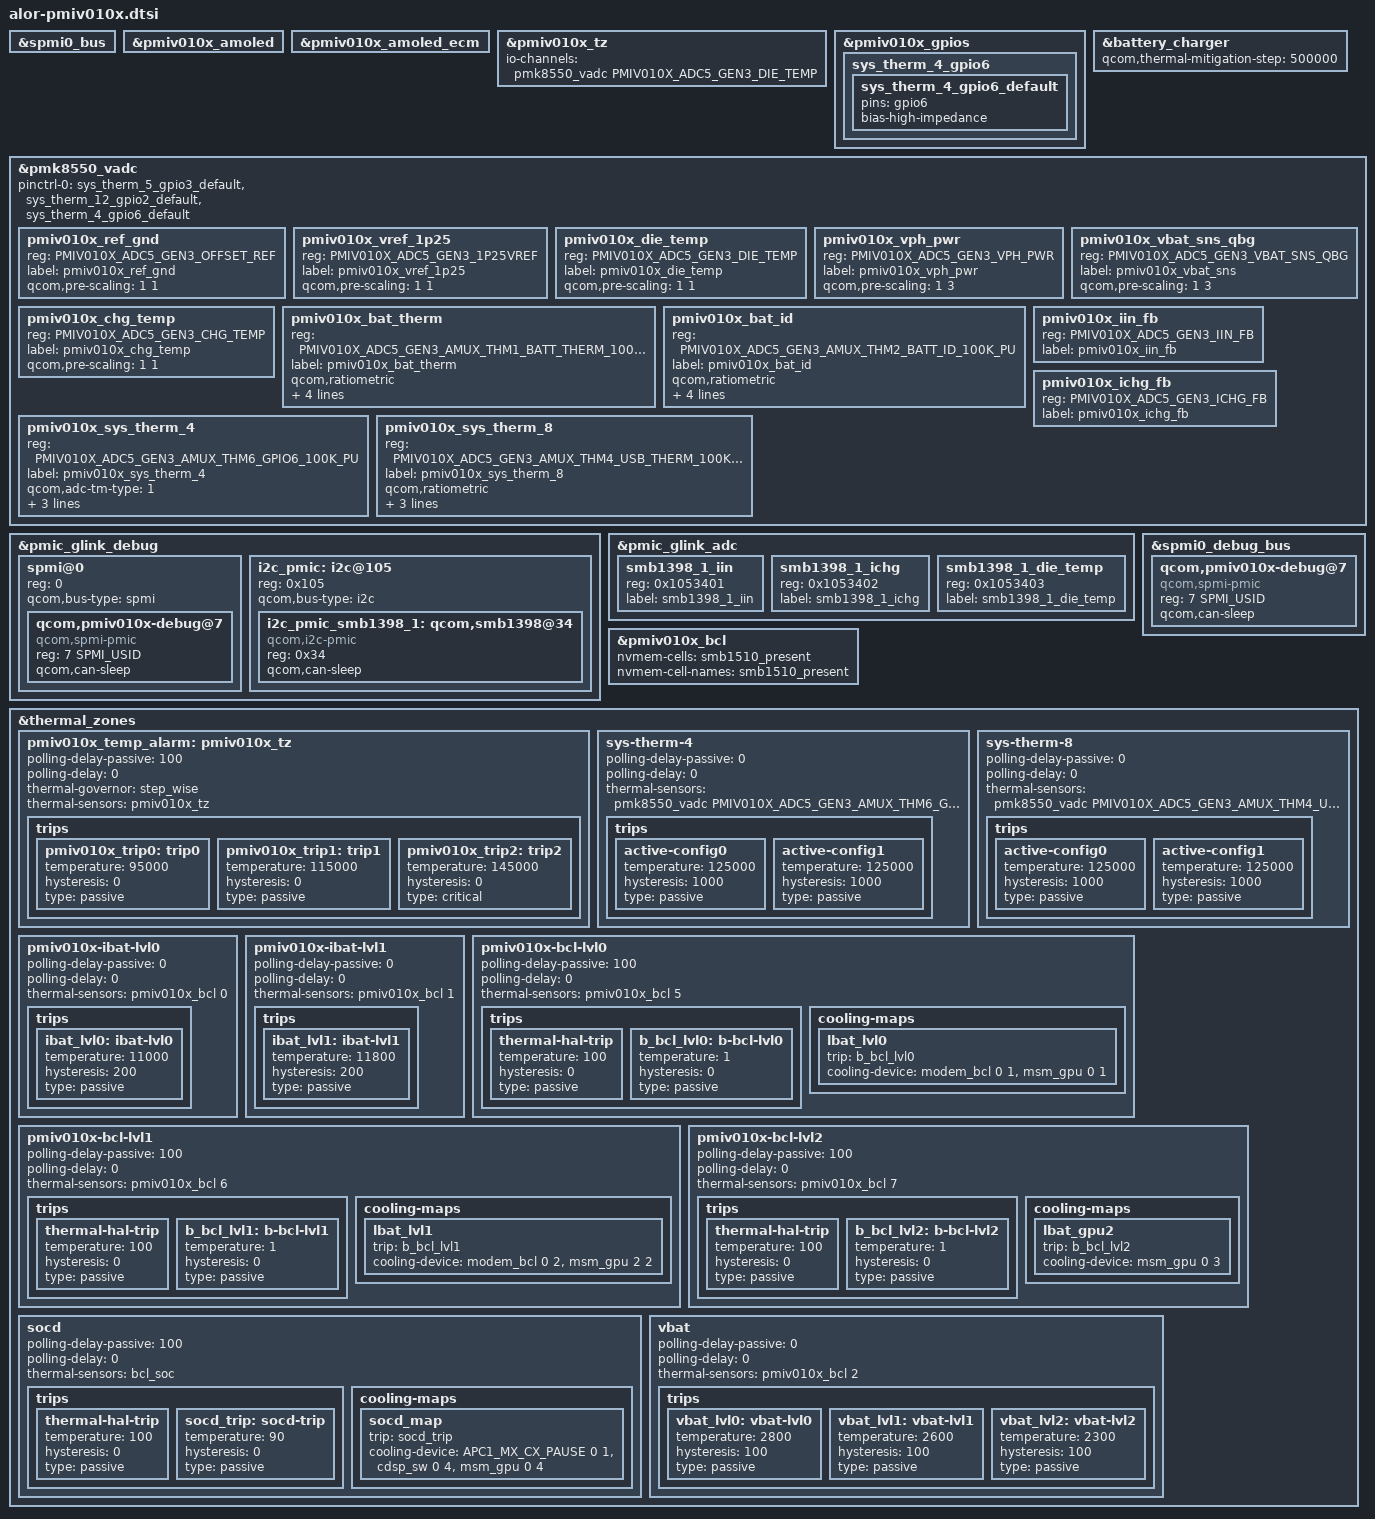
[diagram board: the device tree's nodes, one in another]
// SPDX-License-Identifier: BSD-3-Clause
/*
 * Copyright (c) Qualcomm Technologies, Inc. and/or its subsidiaries.
 */

#include <dt-bindings/iio/qcom,spmi-vadc.h>
#include <dt-bindings/iio/qcom,spmi-adc5-gen3-pmiv010x.h>

&spmi0_bus {
	#include "pmiv010x.dtsi"
};

&pmiv010x_amoled {
	status= "ok";
};

&pmiv010x_amoled_ecm {
	status = "ok";
};

&pmiv010x_tz {
	io-channels = <&pmk8550_vadc PMIV010X_ADC5_GEN3_DIE_TEMP>;
	io-channel-names = "thermal";
};

&pmiv010x_gpios {
	sys_therm_4_gpio6 {
		sys_therm_4_gpio6_default: sys_therm_4_gpio6_default {
			pins = "gpio6";
			bias-high-impedance;
		};
	};
};

&battery_charger {
	#cooling-cells = <2>;
	qcom,thermal-mitigation-step = <500000>;
};

&pmk8550_vadc {
	pinctrl-0 = <&sys_therm_5_gpio3_default>,
			<&sys_therm_12_gpio2_default>,
			<&sys_therm_4_gpio6_default>;
	pinctrl-names = "default";

	pmiv010x_ref_gnd {
		reg = <PMIV010X_ADC5_GEN3_OFFSET_REF>;
		label = "pmiv010x_ref_gnd";
		qcom,pre-scaling = <1 1>;
	};

	pmiv010x_vref_1p25 {
		reg = <PMIV010X_ADC5_GEN3_1P25VREF>;
		label = "pmiv010x_vref_1p25";
		qcom,pre-scaling = <1 1>;
	};

	pmiv010x_die_temp {
		reg = <PMIV010X_ADC5_GEN3_DIE_TEMP>;
		label = "pmiv010x_die_temp";
		qcom,pre-scaling = <1 1>;
	};

	pmiv010x_vph_pwr {
		reg = <PMIV010X_ADC5_GEN3_VPH_PWR>;
		label = "pmiv010x_vph_pwr";
		qcom,pre-scaling = <1 3>;
	};

	pmiv010x_vbat_sns_qbg {
		reg = <PMIV010X_ADC5_GEN3_VBAT_SNS_QBG>;
		label = "pmiv010x_vbat_sns";
		qcom,pre-scaling = <1 3>;
	};

	pmiv010x_chg_temp {
		reg = <PMIV010X_ADC5_GEN3_CHG_TEMP>;
		label = "pmiv010x_chg_temp";
		qcom,pre-scaling = <1 1>;
	};

	pmiv010x_bat_therm {
		reg = <PMIV010X_ADC5_GEN3_AMUX_THM1_BATT_THERM_100K_PU>;
		label = "pmiv010x_bat_therm";
		qcom,ratiometric;
		qcom,hw-settle-time = <200>;
		qcom,pre-scaling = <1 1>;
		qcom,scale-fn-type = <ADC_SCALE_HW_CALIB_PM5_GEN3_BATT_THERM_100K>;
	};

	pmiv010x_bat_id {
		reg = <PMIV010X_ADC5_GEN3_AMUX_THM2_BATT_ID_100K_PU>;
		label = "pmiv010x_bat_id";
		qcom,ratiometric;
		qcom,hw-settle-time = <200>;
		qcom,pre-scaling = <1 1>;
		qcom,scale-fn-type = <ADC_SCALE_HW_CALIB_PM5_GEN3_BATT_ID_100K>;
	};

	pmiv010x_iin_fb {
		reg = <PMIV010X_ADC5_GEN3_IIN_FB>;
		label = "pmiv010x_iin_fb";
	};

	pmiv010x_ichg_fb {
		reg = <PMIV010X_ADC5_GEN3_ICHG_FB>;
		label = "pmiv010x_ichg_fb";
	};

	pmiv010x_sys_therm_4 {
		reg = <PMIV010X_ADC5_GEN3_AMUX_THM6_GPIO6_100K_PU>;
		label = "pmiv010x_sys_therm_4";
		qcom,adc-tm-type = <1>;
		qcom,ratiometric;
		qcom,hw-settle-time = <200>;
		qcom,pre-scaling = <1 1>;
	};

	pmiv010x_sys_therm_8 {
		reg = <PMIV010X_ADC5_GEN3_AMUX_THM4_USB_THERM_100K_PU>;
		label = "pmiv010x_sys_therm_8";
		qcom,ratiometric;
		qcom,hw-settle-time = <200>;
		qcom,pre-scaling = <1 1>;
		qcom,adc-tm-type = <1>;
	};
};

&pmic_glink_debug {
	spmi@0 {
		reg = <0>;
		#address-cells = <2>;
		#size-cells = <0>;
		qcom,bus-type = "spmi";

		qcom,pmiv010x-debug@7 {
			compatible = "qcom,spmi-pmic";
			reg = <7 SPMI_USID>;
			qcom,can-sleep;
		};
	};

	i2c_pmic:i2c@105 {
		reg = <0x105>;  /* I2C instance 5 in ADSP for SE4 */
		#address-cells = <1>;
		#size-cells = <0>;
		qcom,bus-type = "i2c";

		i2c_pmic_smb1398_1: qcom,smb1398@34 {
			compatible = "qcom,i2c-pmic";
			reg = <0x34>;
			qcom,can-sleep;
		};
	};
};

&pmic_glink_adc {
	status = "ok";

	smb1398_1_iin {
		reg = <0x1053401>;
		label = "smb1398_1_iin";
	};

	smb1398_1_ichg {
		reg = <0x1053402>;
		label = "smb1398_1_ichg";
	};

	smb1398_1_die_temp {
		reg = <0x1053403>;
		label = "smb1398_1_die_temp";
	};
};

&spmi0_debug_bus {
	qcom,pmiv010x-debug@7 {
		compatible = "qcom,spmi-pmic";
		reg = <7 SPMI_USID>;
		#address-cells = <2>;
		#size-cells = <0>;
		qcom,can-sleep;
	};
};

&pmiv010x_bcl {
	nvmem-cells = <&smb1510_present>;
	nvmem-cell-names = "smb1510_present";
};

&thermal_zones {
	pmiv010x_temp_alarm: pmiv010x_tz {
		polling-delay-passive = <100>;
		polling-delay = <0>;
		thermal-governor = "step_wise";
		thermal-sensors = <&pmiv010x_tz>;
		trips {
			pmiv010x_trip0: trip0 {
				temperature = <95000>;
				hysteresis = <0>;
				type = "passive";
			};

			pmiv010x_trip1: trip1 {
				temperature = <115000>;
				hysteresis = <0>;
				type = "passive";
			};

			pmiv010x_trip2: trip2 {
				temperature = <145000>;
				hysteresis = <0>;
				type = "critical";
			};
		};
	};

	sys-therm-4 {
		polling-delay-passive = <0>;
		polling-delay = <0>;
		thermal-sensors = <&pmk8550_vadc PMIV010X_ADC5_GEN3_AMUX_THM6_GPIO6_100K_PU>;
		trips {
			active-config0 {
				temperature = <125000>;
				hysteresis = <1000>;
				type = "passive";
			};

			active-config1 {
				temperature = <125000>;
				hysteresis = <1000>;
				type = "passive";
			};
		};
	};

	sys-therm-8 {
		polling-delay-passive = <0>;
		polling-delay = <0>;
		thermal-sensors = <&pmk8550_vadc PMIV010X_ADC5_GEN3_AMUX_THM4_USB_THERM_100K_PU>;
		trips {
			active-config0 {
				temperature = <125000>;
				hysteresis = <1000>;
				type = "passive";
			};

			active-config1 {
				temperature = <125000>;
				hysteresis = <1000>;
				type = "passive";
			};
		};
	};

	pmiv010x-ibat-lvl0 {
		polling-delay-passive = <0>;
		polling-delay = <0>;
		thermal-sensors = <&pmiv010x_bcl 0>;

		trips {
			ibat_lvl0:ibat-lvl0 {
				temperature = <11000>;
				hysteresis = <200>;
				type = "passive";
			};
		};
	};

	pmiv010x-ibat-lvl1 {
		polling-delay-passive = <0>;
		polling-delay = <0>;
		thermal-sensors = <&pmiv010x_bcl 1>;

		trips {
			ibat_lvl1:ibat-lvl1 {
				temperature = <11800>;
				hysteresis = <200>;
				type = "passive";
			};
		};
	};

	pmiv010x-bcl-lvl0 {
		polling-delay-passive = <100>;
		polling-delay = <0>;
		thermal-sensors = <&pmiv010x_bcl 5>;

		trips {
			thermal-hal-trip {
				temperature = <100>;
				hysteresis = <0>;
				type = "passive";
			};

			b_bcl_lvl0: b-bcl-lvl0 {
				temperature = <1>;
				hysteresis = <0>;
				type = "passive";
			};
		};

		cooling-maps {
			lbat_lvl0 {
				trip = <&b_bcl_lvl0>;
				cooling-device = <&modem_bcl 0 1>,
					<&msm_gpu 0 1>;
			};
		};
	};

	pmiv010x-bcl-lvl1 {
		polling-delay-passive = <100>;
		polling-delay = <0>;
		thermal-sensors = <&pmiv010x_bcl 6>;

		trips {
			thermal-hal-trip {
				temperature = <100>;
				hysteresis = <0>;
				type = "passive";
			};

			b_bcl_lvl1: b-bcl-lvl1 {
				temperature = <1>;
				hysteresis = <0>;
				type = "passive";
			};
		};

		cooling-maps {
			lbat_lvl1 {
				trip = <&b_bcl_lvl1>;
				cooling-device = <&modem_bcl 0 2>,
					<&msm_gpu 2 2>;
			};
		};
	};

	pmiv010x-bcl-lvl2 {
		polling-delay-passive = <100>;
		polling-delay = <0>;
		thermal-sensors = <&pmiv010x_bcl 7>;

		trips {
			thermal-hal-trip {
				temperature = <100>;
				hysteresis = <0>;
				type = "passive";
			};

			b_bcl_lvl2: b-bcl-lvl2 {
				temperature = <1>;
				hysteresis = <0>;
				type = "passive";
			};
		};

		cooling-maps {
			lbat_gpu2 {
				trip = <&b_bcl_lvl2>;
				cooling-device = <&msm_gpu 0 3>;
			};
		};
	};

	socd {
		polling-delay-passive = <100>;
		polling-delay = <0>;
		thermal-sensors = <&bcl_soc>;

		trips {
			thermal-hal-trip {
				temperature = <100>;
				hysteresis = <0>;
				type = "passive";
			};

			socd_trip:socd-trip {
				temperature = <90>;
				hysteresis = <0>;
				type = "passive";
			};
		};

		cooling-maps {
			socd_map {
				trip = <&socd_trip>;
				cooling-device = <&APC1_MX_CX_PAUSE 0 1>,
					<&cdsp_sw 0 4>,
					<&msm_gpu 0 4>;
			};
		};
	};

	vbat {
		polling-delay-passive = <0>;
		polling-delay = <0>;
		thermal-sensors = <&pmiv010x_bcl 2>;

		trips {
			vbat_lvl0:vbat-lvl0 {
				temperature = <2800>;
				hysteresis = <100>;
				type = "passive";
			};

			vbat_lvl1:vbat-lvl1 {
				temperature = <2600>;
				hysteresis = <100>;
				type = "passive";
			};

			vbat_lvl2:vbat-lvl2 {
				temperature = <2300>;
				hysteresis = <100>;
				type = "passive";
			};
		};
	};
};
